# STM32WBA25 register map
File version: 1.0
CPU: CM33 r0p1, little endian, MPU, FPU, 4 interrupt priority bits
Registers are 32-bit, read-write, reset 0x0 unless marked. A register's access mark holds for its fields unless they carry their own. Offsets are from the block's base; [hi:lo] are bit positions; {n}, {i} and the like mark numbered series; 'fields as' and 'values as' point back to an identical list.

## DLYBXS1 — DLYB address block description
Base 0x420CF000
Same registers: SEC_DLYBXS1 0x520CF000
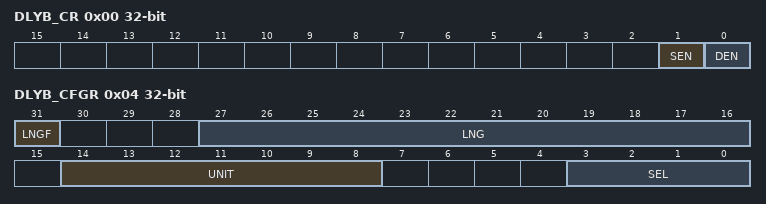
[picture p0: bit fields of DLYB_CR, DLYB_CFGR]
0x00 DLYB_CR — DLYB control register
  [1] SEN — Sampler length enable bit
    0=Sampler length and register access to UNIT[6:0] and SEL[3:0] disabled, output clock enabled; 1=Sampler length and register access to UNIT[6:0] and SEL[3:0] enabled, output clock disabled
  [0] DEN — Delay block enable bit
    0=DLYB disabled; 1=DLYB enabled
0x04 DLYB_CFGR — DLYB configuration register
  [31] LNGF ro — Length valid flag
    0=Length value in LNG is not valid; 1=Length value in LNG is valid
  [27:16] LNG ro — Delay line length value
  [14:8] UNIT — Delay of a unit delay cell.
  [3:0] SEL — Phase for the output clock.

## GPIOC — GPIOC address block description
Base 0x42020800
Same registers: SEC_GPIOC 0x52020800
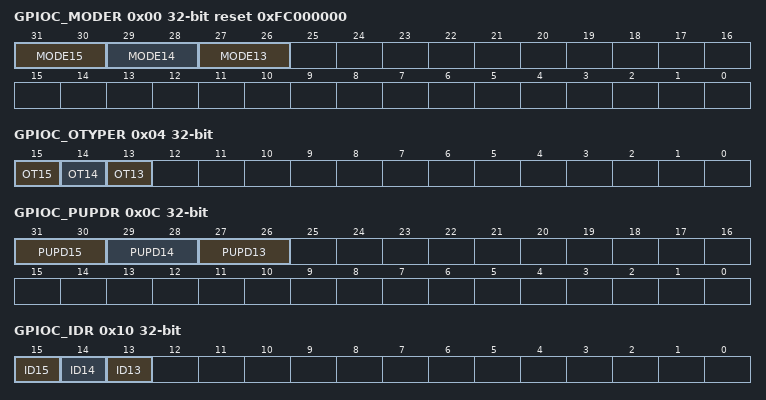
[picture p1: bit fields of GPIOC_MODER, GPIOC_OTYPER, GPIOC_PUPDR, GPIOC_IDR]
0x00 GPIOC_MODER reset 0xFC000000 — GPIO port C mode register
  [31:30] MODE15 — Port C configuration I/O pin 15
    0=Input mode; 1=General purpose output mode; 2=Alternate function mode; 3=Analog mode (reset state)
  [29:28] MODE14 — Port C configuration I/O pin 14
  [27:26] MODE13 — Port C configuration I/O pin 13
0x04 GPIOC_OTYPER — GPIO port C output type register
  [all] fields
    0=Output push-pull (reset state); 1=Output open-drain
  [15] OT15 — Port C configuration I/O pin y
  [14] OT14 — Port C configuration I/O pin y
  [13] OT13 — Port C configuration I/O pin y
0x08 GPIOC_OSPEEDR — GPIOC port output speed register
  [27:26] OSPEED13 — Port C configuration I/O pin 13
    0=Low speed; 1=Medium speed; 2=High speed
0x0C GPIOC_PUPDR — GPIO port C pull-up/pull-down register
  [31:30] PUPD15 — Port C configuration I/O pin 15
    0=No pull-up, pull-down; 1=Pull-up; 2=Pull-down
  [29:28] PUPD14 — Port C configuration I/O pin 14
  [27:26] PUPD13 — Port C configuration I/O pin 13
0x10 GPIOC_IDR ro (reset mask 0xFFFF0FFF) — GPIO port C input data register
  [15] ID15 — Port C input data I/O pin y
  [14] ID14 — Port C input data I/O pin y
  [13] ID13 — Port C input data I/O pin y
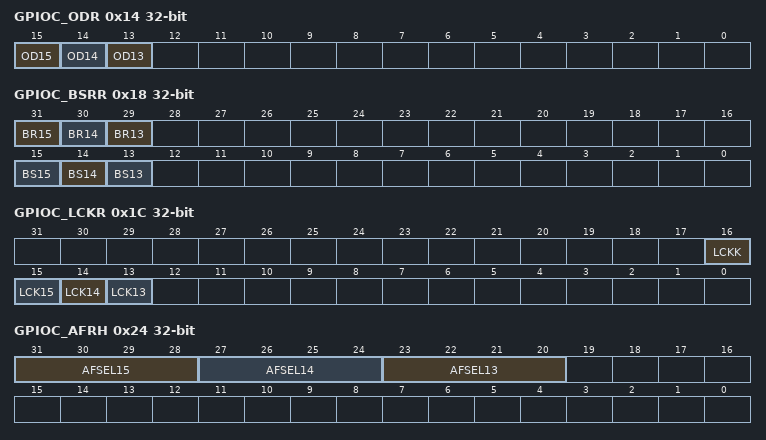
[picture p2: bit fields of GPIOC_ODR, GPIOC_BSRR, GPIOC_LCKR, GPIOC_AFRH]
0x14 GPIOC_ODR — GPIO port C output data register
  [15] OD15 — Port C output data I/O pin y
  [14] OD14 — Port C output data I/O pin y
  [13] OD13 — Port C output data I/O pin y
0x18 GPIOC_BSRR wo — GPIO port C bit set/reset register
  [31] BR15 — Port C reset I/O pin y
    0=No action on the corresponding ODy bit; 1=Resets the corresponding ODy bit
  [30] BR14 — Port C reset I/O pin y
    values as BR15
  [29] BR13 — Port C reset I/O pin y
    values as BR15
  [15] BS15 — Port C set I/O pin y
    0=No action on the corresponding ODy bit; 1=Sets the corresponding ODy bit
  [14] BS14 — Port C set I/O pin y
    values as BS15
  [13] BS13 — Port C set I/O pin y
    values as BS15
0x1C GPIOC_LCKR — GPIO port C configuration lock register
  [16] LCKK — Lock key
    0=Port configuration lock key not active; 1=Port configuration lock key active
  [15] LCK15 — Port C lock I/O pin y
    0=Port configuration not locked; 1=Port configuration locked
  [14] LCK14 — Port C lock I/O pin y
    0=Port configuration not locked; 1=Port configuration locked
  [13] LCK13 — Port C lock I/O pin y
    0=Port configuration not locked; 1=Port configuration locked
0x24 GPIOC_AFRH — GPIO port C alternate function high register
  [31:28] AFSEL15 — Alternate function selection for port C I/O pin 15
    {v}=AF{v} (v=0..15)
  [27:24] AFSEL14 — Alternate function selection for port C I/O pin 14
  [23:20] AFSEL13 — Alternate function selection for port C I/O pin 13
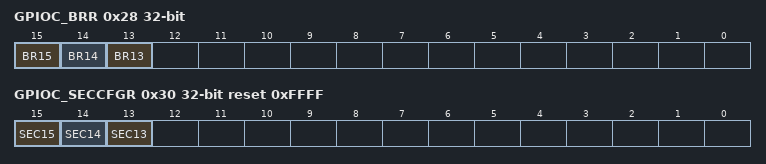
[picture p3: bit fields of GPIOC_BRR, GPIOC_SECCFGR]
0x28 GPIOC_BRR wo — GPIO port C bit reset register
  [all] fields
    0=No action on the corresponding ODy bit; 1=Reset the corresponding ODy bit
  [15] BR15 — Port reset I/O pin y
  [14] BR14 — Port reset I/O pin y
  [13] BR13 — Port reset I/O pin y
0x30 GPIOC_SECCFGR wo reset 0xFFFF — GPIO port C secure configuration register
  [all] fields
    0=The I/O pin is non-secure; 1=The I/O pin is secure
  [15] SEC15 — I/O pin of port C secure bit enable y
  [14] SEC14 — I/O pin of port C secure bit enable y
  [13] SEC13 — I/O pin of port C secure bit enable y
